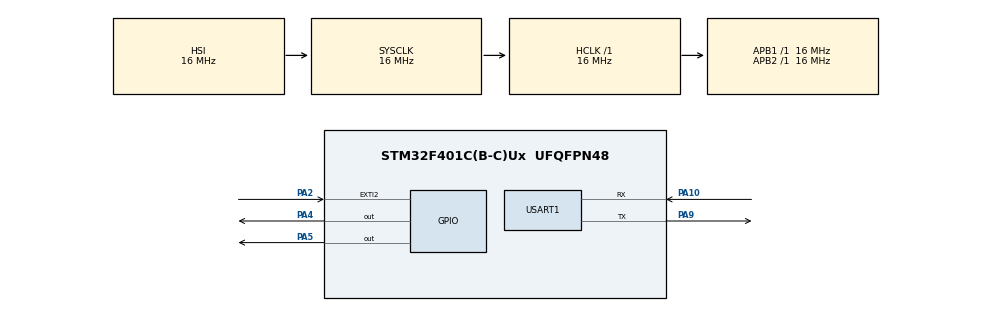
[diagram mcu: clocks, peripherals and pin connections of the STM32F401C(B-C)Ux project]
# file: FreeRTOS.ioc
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FREERTOS.Tasks01=Task1,24,128,StartTask1,Default,NULL,Dynamic,NULL,NULL;Task2,8,128,StartTask02,Default,NULL,Dynamic,NULL,NULL
Mcu.Family=STM32F4
Mcu.Name=STM32F401C(B-C)Ux
Mcu.Package=UFQFPN48
NVIC.EXTI2_IRQn=true\:0\:0\:false\:false\:true\:false\:true\:true\:true
NVIC.PriorityGroup=NVIC_PRIORITYGROUP_4
NVIC.TIM3_IRQn=true\:15\:0\:false\:false\:true\:false\:false\:true\:true
NVIC.TimeBase=TIM3_IRQn
NVIC.TimeBaseIP=TIM3
NVIC.USART1_IRQn=true\:5\:0\:false\:false\:true\:true\:true\:true\:true
PA10.Mode=Asynchronous
PA10.Signal=USART1_RX
PA2.GPIO_ModeDefaultEXTI=GPIO_MODE_IT_FALLING
PA2.GPIO_PuPd=GPIO_PULLUP
PA2.Signal=GPXTI2
PA4.Signal=GPIO_Output
PA5.Signal=GPIO_Output
PA9.Mode=Asynchronous
PA9.Signal=USART1_TX
ProjectManager.HeapSize=0x200
ProjectManager.StackSize=0x400
ProjectManager.TargetToolchain=STM32CubeIDE
RCC.AHBFreq_Value=16000000
RCC.APB1Freq_Value=16000000
RCC.APB2Freq_Value=16000000
RCC.CortexFreq_Value=16000000
RCC.HSE_VALUE=25000000
RCC.HSI_VALUE=16000000
RCC.LSE_VALUE=32768
RCC.SYSCLKFreq_VALUE=16000000
RCC.VCOOutputFreq_Value=192000000
USART1.VirtualMode=VM_ASYNC
VP_FREERTOS_VS_CMSIS_V2.Mode=CMSIS_V2
VP_SYS_VS_tim3.Mode=TIM3
board=custom

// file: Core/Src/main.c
/* USER CODE BEGIN Header */
/**
  ******************************************************************************
  * @file           : main.c
  * @brief          : Main program body
  ******************************************************************************
  * @attention
  *
  * Copyright (c) 2025 STMicroelectronics.
  * All rights reserved.
  *
  * This software is licensed under terms that can be found in the LICENSE file
  * in the root directory of this software component.
  * If no LICENSE file comes with this software, it is provided AS-IS.
  *
  ******************************************************************************
  */
/* USER CODE END Header */
#include "main.h"
#include "cmsis_os.h"

UART_HandleTypeDef huart1;

/* Definitions for Task1 */
osThreadId_t Task1Handle;
const osThreadAttr_t Task1_attributes = {
  .name = "Task1",
  .stack_size = 128 * 4,
  .priority = (osPriority_t) osPriorityNormal,
};
/* Definitions for Task2 */
osThreadId_t Task2Handle;
const osThreadAttr_t Task2_attributes = {
  .name = "Task2",
  .stack_size = 128 * 4,
  .priority = (osPriority_t) osPriorityLow,
};
/* USER CODE BEGIN PV */
volatile int taskSwitchFlag = 0;  // Flag to indicate task switch
/* USER CODE END PV */

void SystemClock_Config(void);
static void MX_GPIO_Init(void);
static void MX_USART1_UART_Init(void);
void StartTask1(void *argument);
void StartTask02(void *argument);

int main(void)
{

  /* MCU Configuration--------------------------------------------------------*/

  /* Reset of all peripherals, Initializes the Flash interface and the Systick. */
  HAL_Init();

  /* Configure the system clock */
  SystemClock_Config();

  /* Initialize all configured peripherals */
  MX_GPIO_Init();
  MX_USART1_UART_Init();

  /* Init scheduler */
  osKernelInitialize();

  /* Create the thread(s) */
  /* creation of Task1 */
  Task1Handle = osThreadNew(StartTask1, NULL, &Task1_attributes);

  /* creation of Task2 */
  Task2Handle = osThreadNew(StartTask02, NULL, &Task2_attributes);

  /* Start scheduler */
  osKernelStart();

  /* We should never get here as control is now taken by the scheduler */

  /* Infinite loop */
  while (1)
  {

  }
}

void SystemClock_Config(void)
{
  RCC_OscInitTypeDef RCC_OscInitStruct = {0};
  RCC_ClkInitTypeDef RCC_ClkInitStruct = {0};

  /** Configure the main internal regulator output voltage
  */
  __HAL_RCC_PWR_CLK_ENABLE();
  __HAL_PWR_VOLTAGESCALING_CONFIG(PWR_REGULATOR_VOLTAGE_SCALE2);

  /** Initializes the RCC Oscillators according to the specified parameters
  * in the RCC_OscInitTypeDef structure.
  */
  RCC_OscInitStruct.OscillatorType = RCC_OSCILLATORTYPE_HSI;
  RCC_OscInitStruct.HSIState = RCC_HSI_ON;
  RCC_OscInitStruct.HSICalibrationValue = RCC_HSICALIBRATION_DEFAULT;
  RCC_OscInitStruct.PLL.PLLState = RCC_PLL_NONE;
  if (HAL_RCC_OscConfig(&RCC_OscInitStruct) != HAL_OK)
  {
    Error_Handler();
  }

  /** Initializes the CPU, AHB and APB buses clocks
  */
  RCC_ClkInitStruct.ClockType = RCC_CLOCKTYPE_HCLK|RCC_CLOCKTYPE_SYSCLK
                              |RCC_CLOCKTYPE_PCLK1|RCC_CLOCKTYPE_PCLK2;
  RCC_ClkInitStruct.SYSCLKSource = RCC_SYSCLKSOURCE_HSI;
  RCC_ClkInitStruct.AHBCLKDivider = RCC_SYSCLK_DIV1;
  RCC_ClkInitStruct.APB1CLKDivider = RCC_HCLK_DIV1;
  RCC_ClkInitStruct.APB2CLKDivider = RCC_HCLK_DIV1;

  if (HAL_RCC_ClockConfig(&RCC_ClkInitStruct, FLASH_LATENCY_0) != HAL_OK)
  {
    Error_Handler();
  }
}

static void MX_USART1_UART_Init(void)
{

  huart1.Instance = USART1;
  huart1.Init.BaudRate = 115200;
  huart1.Init.WordLength = UART_WORDLENGTH_8B;
  huart1.Init.StopBits = UART_STOPBITS_1;
  huart1.Init.Parity = UART_PARITY_NONE;
  huart1.Init.Mode = UART_MODE_TX_RX;
  huart1.Init.HwFlowCtl = UART_HWCONTROL_NONE;
  huart1.Init.OverSampling = UART_OVERSAMPLING_16;
  if (HAL_UART_Init(&huart1) != HAL_OK)
  {
    Error_Handler();
  }

}

static void MX_GPIO_Init(void)
{
  GPIO_InitTypeDef GPIO_InitStruct = {0};

  /* GPIO Ports Clock Enable */
  __HAL_RCC_GPIOA_CLK_ENABLE();

  /*Configure GPIO pin Output Level */
  HAL_GPIO_WritePin(GPIOA, GPIO_PIN_4|GPIO_PIN_5, GPIO_PIN_RESET);

  /*Configure GPIO pin : PA2 */
  GPIO_InitStruct.Pin = GPIO_PIN_2;
  GPIO_InitStruct.Mode = GPIO_MODE_IT_FALLING;
  GPIO_InitStruct.Pull = GPIO_PULLUP;
  HAL_GPIO_Init(GPIOA, &GPIO_InitStruct);

  /*Configure GPIO pins : PA4 PA5 */
  GPIO_InitStruct.Pin = GPIO_PIN_4|GPIO_PIN_5;
  GPIO_InitStruct.Mode = GPIO_MODE_OUTPUT_PP;
  GPIO_InitStruct.Pull = GPIO_NOPULL;
  GPIO_InitStruct.Speed = GPIO_SPEED_FREQ_LOW;
  HAL_GPIO_Init(GPIOA, &GPIO_InitStruct);

  /* EXTI interrupt init*/
  HAL_NVIC_SetPriority(EXTI2_IRQn, 0, 0);
  HAL_NVIC_EnableIRQ(EXTI2_IRQn);

}

/* USER CODE BEGIN 4 */
/* USER CODE BEGIN 4 */

/* This function will be called when the EXTI interrupt occurs */
/* USER CODE END 4 */
/* USER CODE END 4 */

void StartTask1(void *argument)
{
  /* USER CODE BEGIN 5 */
  /* Infinite loop */
  for(;;)
  {
        HAL_GPIO_WritePin(GPIOA, GPIO_PIN_4, 1);
        osDelay(1000);
        HAL_GPIO_WritePin(GPIOA, GPIO_PIN_4, 0);
        osDelay(1000);

  }
  /* USER CODE END 5 */
}

void StartTask02(void *argument)
{
  /* USER CODE BEGIN StartTask02 */
  /* Infinite loop */
  for(;;)
  {

	HAL_GPIO_WritePin(GPIOA, GPIO_PIN_5, 1);
	osDelay(1000);
	HAL_GPIO_WritePin(GPIOA, GPIO_PIN_5, 0);
	osDelay(1000);

  }
  /* USER CODE END StartTask02 */
}

void HAL_TIM_PeriodElapsedCallback(TIM_HandleTypeDef *htim)
{
  if (htim->Instance == TIM3) {
    HAL_IncTick();
  }
}

void Error_Handler(void)
{
  __disable_irq();
  while (1)
  {
  }
}
